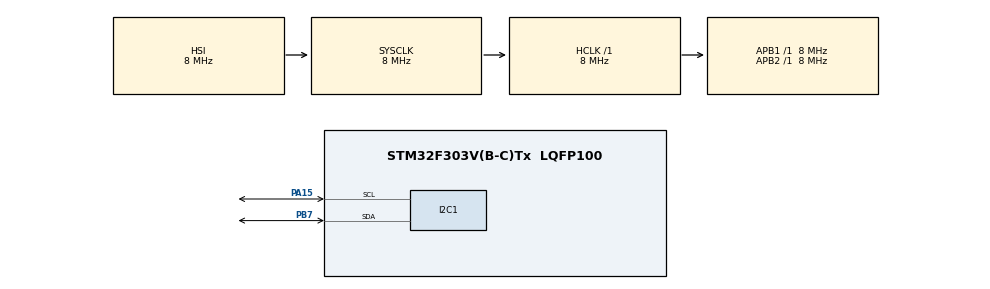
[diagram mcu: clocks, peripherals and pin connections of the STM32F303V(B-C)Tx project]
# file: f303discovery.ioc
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Mcu.Family=STM32F3
Mcu.Name=STM32F303V(B-C)Tx
Mcu.Package=LQFP100
NVIC.I2C1_ER_IRQn=true\:0\:0\:false\:false\:true\:true\:true\:true
NVIC.I2C1_EV_IRQn=true\:0\:0\:false\:false\:true\:true\:true\:true
NVIC.PriorityGroup=NVIC_PRIORITYGROUP_4
PA13.Mode=Serial_Wire
PA13.Signal=SYS_JTMS-SWDIO
PA14.Mode=Serial_Wire
PA14.Signal=SYS_JTCK-SWCLK
PA15.Mode=I2C
PA15.Signal=I2C1_SCL
PB7.Mode=I2C
PB7.Signal=I2C1_SDA
PF0-OSC_IN.Mode=HSE-External-Oscillator
PF0-OSC_IN.Signal=RCC_OSC_IN
PF1-OSC_OUT.Mode=HSE-External-Oscillator
PF1-OSC_OUT.Signal=RCC_OSC_OUT
ProjectManager.HeapSize=0x200
ProjectManager.StackSize=0x400
ProjectManager.TargetToolchain=STM32CubeIDE
RCC.AHBFreq_Value=8000000
RCC.APB1Freq_Value=8000000
RCC.APB2Freq_Value=8000000
RCC.CortexFreq_Value=8000000
RCC.HSE_VALUE=8000000
RCC.HSI_VALUE=8000000
RCC.LSE_VALUE=32768
RCC.SYSCLKFreq_VALUE=8000000
TIM4.Period=1000-1
TIM4.Prescaler=7200-1
VP_TIM4_VS_ClockSourceINT.Mode=Internal
board=custom

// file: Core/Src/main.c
/* USER CODE BEGIN Header */
/**
  ******************************************************************************
  * @file           : main.c
  * @brief          : Main program body
  ******************************************************************************
  * @attention
  *
  * Copyright (c) 2022 STMicroelectronics.
  * All rights reserved.
  *
  * This software is licensed under terms that can be found in the LICENSE file
  * in the root directory of this software component.
  * If no LICENSE file comes with this software, it is provided AS-IS.
  *
  ******************************************************************************
  */
/* USER CODE END Header */
#include "main.h"

/* USER CODE BEGIN Includes */
#include "lcd-i2c.h"
#include <math.h>
#include <stdio.h>

/* Variables for AHT10 */
uint8_t AHT10_RX_Data[6];
uint32_t AHT10_ADC_Raw;
float AHT10_Temperature;
float AHT10_Humidity;
uint8_t AHT10_TmpHum_Cmd = 0xAC;
#define AHT10_Adress 0x38 << 1

uint8_t T_100ms = 255;
uint8_t AHT10_Switcher = 255;

char buf[60];
/* USER CODE END Includes */

 I2C_HandleTypeDef hi2c1;

TIM_HandleTypeDef htim4;

void SystemClock_Config(void);
static void MX_GPIO_Init(void);
static void MX_I2C1_Init(void);
static void MX_TIM4_Init(void);

int main(void)
{

  /* MCU Configuration--------------------------------------------------------*/

  /* Reset of all peripherals, Initializes the Flash interface and the Systick. */
  HAL_Init();

  /* Configure the system clock */
  SystemClock_Config();

  /* Initialize all configured peripherals */
  MX_GPIO_Init();
  MX_I2C1_Init();
  MX_TIM4_Init();
  /* USER CODE BEGIN 2 */
lcd_init();

  /* USER CODE END 2 */

  /* Infinite loop */
  while (1)
  {

    /* USER CODE BEGIN 3 */
	  HAL_I2C_Master_Transmit(&hi2c1, AHT10_Adress, &AHT10_TmpHum_Cmd, 1, 100);
	 	  HAL_Delay(100); // Delay must be > 75 ms
	 	  HAL_I2C_Master_Receive(&hi2c1, AHT10_Adress, (uint8_t*)AHT10_RX_Data, 6, 100);
	 	  /* Convert to Temperature in °C */
	 	  AHT10_ADC_Raw = (((uint32_t)AHT10_RX_Data[3] & 15) << 16) | ((uint32_t)AHT10_RX_Data[4] << 8) | AHT10_RX_Data[5];
	 	  AHT10_Temperature = (float)(AHT10_ADC_Raw * 200.00 / 1048576.00) - 50.00;
	 	  AHT10_ADC_Raw = ((uint32_t)AHT10_RX_Data[1] << 12) | ((uint32_t)AHT10_RX_Data[2] << 4) | (AHT10_RX_Data[3] >> 4);
	 	  AHT10_Humidity = (float)(AHT10_ADC_Raw*100.00/1048576.00);
	 	  HAL_Delay(50);

	 	      lcd_put_cur(0,0);
	 	  	 // snprintf(buf, sizeof(buf), "%.1f", AHT10_Temperature);
	 	  	 snprintf(buf, sizeof(buf), "Temp = %.1f", AHT10_Temperature);
	 	  	  puts(buf);
	 		  lcd_send_string(buf);

	 	  	  lcd_put_cur(1,0);
	 	  	  snprintf(buf, sizeof(buf), "Hum = %.1f", AHT10_Humidity);
	 	  	  puts(buf);
	 	  	  lcd_send_string(buf);

  }
  /* USER CODE END 3 */
}

void SystemClock_Config(void)
{
  RCC_OscInitTypeDef RCC_OscInitStruct = {0};
  RCC_ClkInitTypeDef RCC_ClkInitStruct = {0};
  RCC_PeriphCLKInitTypeDef PeriphClkInit = {0};

  /** Initializes the RCC Oscillators according to the specified parameters
  * in the RCC_OscInitTypeDef structure.
  */
  RCC_OscInitStruct.OscillatorType = RCC_OSCILLATORTYPE_HSI;
  RCC_OscInitStruct.HSIState = RCC_HSI_ON;
  RCC_OscInitStruct.HSICalibrationValue = RCC_HSICALIBRATION_DEFAULT;
  RCC_OscInitStruct.PLL.PLLState = RCC_PLL_NONE;
  if (HAL_RCC_OscConfig(&RCC_OscInitStruct) != HAL_OK)
  {
    Error_Handler();
  }

  /** Initializes the CPU, AHB and APB buses clocks
  */
  RCC_ClkInitStruct.ClockType = RCC_CLOCKTYPE_HCLK|RCC_CLOCKTYPE_SYSCLK
                              |RCC_CLOCKTYPE_PCLK1|RCC_CLOCKTYPE_PCLK2;
  RCC_ClkInitStruct.SYSCLKSource = RCC_SYSCLKSOURCE_HSI;
  RCC_ClkInitStruct.AHBCLKDivider = RCC_SYSCLK_DIV1;
  RCC_ClkInitStruct.APB1CLKDivider = RCC_HCLK_DIV1;
  RCC_ClkInitStruct.APB2CLKDivider = RCC_HCLK_DIV1;

  if (HAL_RCC_ClockConfig(&RCC_ClkInitStruct, FLASH_LATENCY_0) != HAL_OK)
  {
    Error_Handler();
  }
  PeriphClkInit.PeriphClockSelection = RCC_PERIPHCLK_I2C1;
  PeriphClkInit.I2c1ClockSelection = RCC_I2C1CLKSOURCE_HSI;
  if (HAL_RCCEx_PeriphCLKConfig(&PeriphClkInit) != HAL_OK)
  {
    Error_Handler();
  }
}

static void MX_I2C1_Init(void)
{

  hi2c1.Instance = I2C1;
  hi2c1.Init.Timing = 0x2000090E;
  hi2c1.Init.OwnAddress1 = 0;
  hi2c1.Init.AddressingMode = I2C_ADDRESSINGMODE_7BIT;
  hi2c1.Init.DualAddressMode = I2C_DUALADDRESS_DISABLE;
  hi2c1.Init.OwnAddress2 = 0;
  hi2c1.Init.OwnAddress2Masks = I2C_OA2_NOMASK;
  hi2c1.Init.GeneralCallMode = I2C_GENERALCALL_DISABLE;
  hi2c1.Init.NoStretchMode = I2C_NOSTRETCH_DISABLE;
  if (HAL_I2C_Init(&hi2c1) != HAL_OK)
  {
    Error_Handler();
  }

  /** Configure Analogue filter
  */
  if (HAL_I2CEx_ConfigAnalogFilter(&hi2c1, I2C_ANALOGFILTER_ENABLE) != HAL_OK)
  {
    Error_Handler();
  }

  /** Configure Digital filter
  */
  if (HAL_I2CEx_ConfigDigitalFilter(&hi2c1, 0) != HAL_OK)
  {
    Error_Handler();
  }

}

static void MX_TIM4_Init(void)
{

  TIM_ClockConfigTypeDef sClockSourceConfig = {0};
  TIM_MasterConfigTypeDef sMasterConfig = {0};

  htim4.Instance = TIM4;
  htim4.Init.Prescaler = 7200-1;
  htim4.Init.CounterMode = TIM_COUNTERMODE_UP;
  htim4.Init.Period = 1000-1;
  htim4.Init.ClockDivision = TIM_CLOCKDIVISION_DIV1;
  htim4.Init.AutoReloadPreload = TIM_AUTORELOAD_PRELOAD_DISABLE;
  if (HAL_TIM_Base_Init(&htim4) != HAL_OK)
  {
    Error_Handler();
  }
  sClockSourceConfig.ClockSource = TIM_CLOCKSOURCE_INTERNAL;
  if (HAL_TIM_ConfigClockSource(&htim4, &sClockSourceConfig) != HAL_OK)
  {
    Error_Handler();
  }
  sMasterConfig.MasterOutputTrigger = TIM_TRGO_RESET;
  sMasterConfig.MasterSlaveMode = TIM_MASTERSLAVEMODE_DISABLE;
  if (HAL_TIMEx_MasterConfigSynchronization(&htim4, &sMasterConfig) != HAL_OK)
  {
    Error_Handler();
  }

}

static void MX_GPIO_Init(void)
{

  /* GPIO Ports Clock Enable */
  __HAL_RCC_GPIOF_CLK_ENABLE();
  __HAL_RCC_GPIOA_CLK_ENABLE();
  __HAL_RCC_GPIOB_CLK_ENABLE();

}

void Error_Handler(void)
{
  __disable_irq();
  while (1)
  {
  }
}
